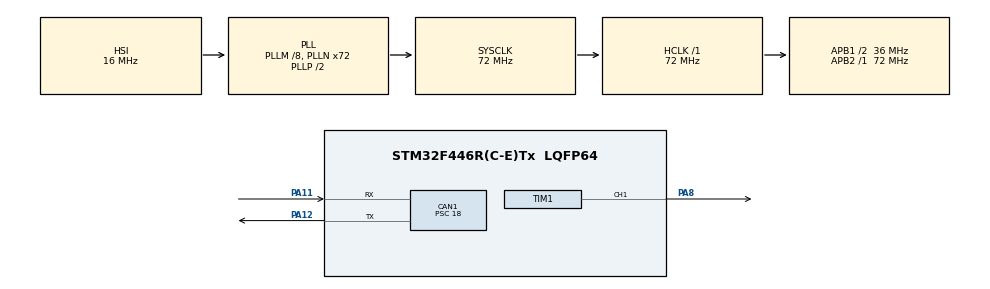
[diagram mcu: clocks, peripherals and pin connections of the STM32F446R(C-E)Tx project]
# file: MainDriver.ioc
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CAN1.BS1=CAN_BS1_2TQ
CAN1.CalculateBaudRate=500000
CAN1.CalculateTimeBit=2000
CAN1.CalculateTimeQuantum=500.0
CAN1.Prescaler=18
Mcu.Family=STM32F4
Mcu.Name=STM32F446R(C-E)Tx
Mcu.Package=LQFP64
NVIC.CAN1_RX0_IRQn=true\:0\:0\:false\:false\:true\:true\:true\:true
NVIC.PriorityGroup=NVIC_PRIORITYGROUP_4
PA11.Mode=CAN_Activate
PA11.Signal=CAN1_RX
PA12.Mode=CAN_Activate
PA12.Signal=CAN1_TX
PA8.Signal=S_TIM1_CH1
PH0-OSC_IN.Mode=HSE-External-Oscillator
PH0-OSC_IN.Signal=RCC_OSC_IN
PH1-OSC_OUT.Mode=HSE-External-Oscillator
PH1-OSC_OUT.Signal=RCC_OSC_OUT
ProjectManager.HeapSize=0x200
ProjectManager.StackSize=0x400
ProjectManager.TargetToolchain=STM32CubeIDE
RCC.AHBFreq_Value=72000000
RCC.APB1CLKDivider=RCC_HCLK_DIV2
RCC.APB1Freq_Value=36000000
RCC.APB1TimFreq_Value=72000000
RCC.APB2Freq_Value=72000000
RCC.APB2TimFreq_Value=72000000
RCC.CortexFreq_Value=72000000
RCC.HCLKFreq_Value=72000000
RCC.PLLM=8
RCC.PLLN=72
RCC.SYSCLKFreq_VALUE=72000000
RCC.SYSCLKSource=RCC_SYSCLKSOURCE_PLLCLK
RCC.USBFreq_Value=72000000
RCC.VCOOutputFreq_Value=144000000
SH.S_TIM1_CH1.0=TIM1_CH1,PWM Generation1 CH1
TIM1.Channel-PWM\ Generation1\ CH1=TIM_CHANNEL_1
TIM1.Prescaler=72-1
board=custom

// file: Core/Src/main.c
/* USER CODE BEGIN Header */
/**
  ******************************************************************************
  * @file           : main.c
  * @brief          : Main program body
  ******************************************************************************
  * @attention
  *
  * Copyright (c) 2024 STMicroelectronics.
  * All rights reserved.
  *
  * This software is licensed under terms that can be found in the LICENSE file
  * in the root directory of this software component.
  * If no LICENSE file comes with this software, it is provided AS-IS.
  *
  ******************************************************************************
  */
/* USER CODE END Header */
#include "main.h"
#include "can.h"
#include "tim.h"
#include "gpio.h"

/* USER CODE BEGIN Includes */
#include <math.h>
/* USER CODE END Includes */

/* USER CODE BEGIN PV */
CAN_TxHeaderTypeDef TxHeader;
CAN_RxHeaderTypeDef RxHeader;

uint32_t TxMailbox;
uint32_t frequency, duty_cycle;
uint32_t capture_value;

uint8_t TxData[8];
uint8_t RxData[8];

int datacheck = 0;

/* USER CODE END PV */

void SystemClock_Config(void);
/* USER CODE BEGIN PFP */
int CAN_MESSAGE_CONVERSION(uint8_t *RxData, int length){
 	int x = 0;
 	int len = length - 1;
 	for(int i = 0; i <= len; i++){
 		x += RxData[len-i] * pow(16, i*2);
 	}
 	return x;
}
/* USER CODE END PFP */

/* USER CODE BEGIN 0 */
void HAL_CAN_RxFifo0MsgPendingCallback(CAN_HandleTypeDef *hcan)
{
	HAL_CAN_GetRxMessage(hcan, CAN_RX_FIFO0, &RxHeader, RxData);
	datacheck = 1;
}

void HAL_TIM_IC_CaptureCallback(TIM_HandleTypeDef *htim) {
	if(htim ->Channel == HAL_TIM_ACTIVE_CHANNEL_1) {
		capture_value = HAL_TIM_ReadCapturedValue(htim, TIM_CHANNEL_1);
		if(capture_value) {
			frequency = SystemCoreClock / (capture_value);
			duty_cycle = 10000 * HAL_TIM_ReadCapturedValue(htim, TIM_CHANNEL_2) / capture_value;
		}
	}
}
/* USER CODE END 0 */

int main(void)
{

  /* MCU Configuration--------------------------------------------------------*/

  /* Reset of all peripherals, Initializes the Flash interface and the Systick. */
  HAL_Init();

  /* Configure the system clock */
  SystemClock_Config();

  /* Initialize all configured peripherals */
  MX_GPIO_Init();
  MX_CAN1_Init();
  MX_TIM1_Init();
  /* USER CODE BEGIN 2 */
  HAL_CAN_Start(&hcan1);

  HAL_CAN_ActivateNotification(&hcan1, CAN_IT_RX_FIFO0_MSG_PENDING);
  HAL_TIM_PWM_Start(&htim1, TIM_CHANNEL_1);
  TxHeader.DLC = 8;
  TxHeader.IDE = CAN_ID_EXT;
  TxHeader.RTR = CAN_RTR_DATA;
  TxHeader.ExtId = 400;
  /* USER CODE END 2 */

  /* Infinite loop */
  while (1)
  {

    /* USER CODE BEGIN 3 */
	int x;
	if(datacheck){
		if(RxHeader.ExtId == 783 || RxHeader.ExtId == 784 || RxHeader.ExtId == 785 || RxHeader.ExtId == 786){
			datacheck = 0;
		}
		if(RxHeader.ExtId == 30){
			datacheck = 0;
		}
		if(RxHeader.ExtId == 31){
			datacheck = 0;
		}
	}
  }
  /* USER CODE END 3 */
}

void SystemClock_Config(void)
{
  RCC_OscInitTypeDef RCC_OscInitStruct = {0};
  RCC_ClkInitTypeDef RCC_ClkInitStruct = {0};

  /** Configure the main internal regulator output voltage
  */
  __HAL_RCC_PWR_CLK_ENABLE();
  __HAL_PWR_VOLTAGESCALING_CONFIG(PWR_REGULATOR_VOLTAGE_SCALE3);

  /** Initializes the RCC Oscillators according to the specified parameters
  * in the RCC_OscInitTypeDef structure.
  */
  RCC_OscInitStruct.OscillatorType = RCC_OSCILLATORTYPE_HSI;
  RCC_OscInitStruct.HSIState = RCC_HSI_ON;
  RCC_OscInitStruct.HSICalibrationValue = RCC_HSICALIBRATION_DEFAULT;
  RCC_OscInitStruct.PLL.PLLState = RCC_PLL_ON;
  RCC_OscInitStruct.PLL.PLLSource = RCC_PLLSOURCE_HSI;
  RCC_OscInitStruct.PLL.PLLM = 8;
  RCC_OscInitStruct.PLL.PLLN = 72;
  RCC_OscInitStruct.PLL.PLLP = RCC_PLLP_DIV2;
  RCC_OscInitStruct.PLL.PLLQ = 2;
  RCC_OscInitStruct.PLL.PLLR = 2;
  if (HAL_RCC_OscConfig(&RCC_OscInitStruct) != HAL_OK)
  {
    Error_Handler();
  }

  /** Initializes the CPU, AHB and APB buses clocks
  */
  RCC_ClkInitStruct.ClockType = RCC_CLOCKTYPE_HCLK|RCC_CLOCKTYPE_SYSCLK
                              |RCC_CLOCKTYPE_PCLK1|RCC_CLOCKTYPE_PCLK2;
  RCC_ClkInitStruct.SYSCLKSource = RCC_SYSCLKSOURCE_PLLCLK;
  RCC_ClkInitStruct.AHBCLKDivider = RCC_SYSCLK_DIV1;
  RCC_ClkInitStruct.APB1CLKDivider = RCC_HCLK_DIV2;
  RCC_ClkInitStruct.APB2CLKDivider = RCC_HCLK_DIV1;

  if (HAL_RCC_ClockConfig(&RCC_ClkInitStruct, FLASH_LATENCY_2) != HAL_OK)
  {
    Error_Handler();
  }
}

void Error_Handler(void)
{
  __disable_irq();
  while (1)
  {
  }
}
